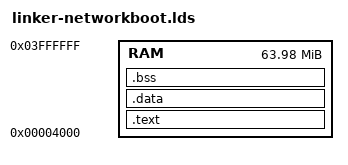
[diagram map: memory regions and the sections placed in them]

ENTRY(_start)

MEMORY
{
        /* a.out-style kernel network boot is fixed @ 0x00004000 */
        RAM : ORIGIN = 0x00004000, LENGTH = 64M - 0x00004000
}

SECTIONS
{
        /**********************************************************************
         *                                                                    *
         **********************************************************************/
        .text :
        {
                _stext = .;
                *(.startup)
                *(.text)
                *(.text.*)
                *(.rodata)
                *(.rodata.*)
                . = ALIGN(0x1000);
                *(.traptable)
                . = ALIGN(0x10);
                _etext = .;
        } > RAM
        /**********************************************************************
         *                                                                    *
         **********************************************************************/
        .data :
        {
                _sdata = .;
                *(.data)
                *(.data.*)
                *(.sdata.*)
                _sdata2 = .;
                *(.sdata2)
                . = ALIGN(0x10);
                _edata = .;
        } > RAM
        /**********************************************************************
         *                                                                    *
         **********************************************************************/
        .bss ADDR(.data) + SIZEOF(.data) (NOLOAD) :
        {
                _sbss = .;
                *(.bss)
                *(.bss.*)
                *(COMMON)
                . = ALIGN(0x10);
                _ebss = .;
        } > RAM
        /**********************************************************************
         *                                                                    *
         **********************************************************************/
        /* no debug symbols for aout-style executables */
        /**********************************************************************
         *                                                                    *
         **********************************************************************/
        /DISCARD/ :
        {
                *(*)
        }
}

/* export to core/linker.ad[s|b] */
/* LINKERADSB:_stext:SText */
/* LINKERADSB:_sdata:SData */
/* LINKERADSB:_sbss:SBss   */

